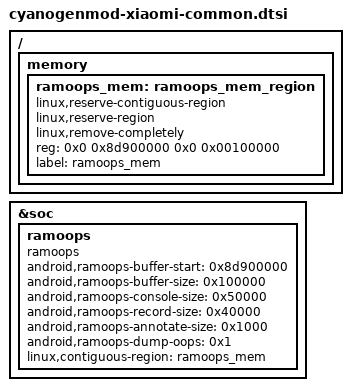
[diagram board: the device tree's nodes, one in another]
/* Copyright (c) 2015, The Linux Foundation. All rights reserved.
 *
 * This program is free software; you can redistribute it and/or modify
 * it under the terms of the GNU General Public License version 2 and
 * only version 2 as published by the Free Software Foundation.
 *
 * This program is distributed in the hope that it will be useful,
 * but WITHOUT ANY WARRANTY; without even the implied warranty of
 * MERCHANTABILITY or FITNESS FOR A PARTICULAR PURPOSE.  See the
 * GNU General Public License for more details.
 */

/ {
	memory {
		ramoops_mem: ramoops_mem_region {
			linux,reserve-contiguous-region;
			linux,reserve-region;
			linux,remove-completely;
			reg = <0x0 0x8d900000 0x0 0x00100000>;
			label = "ramoops_mem";
		};
	};
};

&soc {
	ramoops {
		compatible = "ramoops";
		status = "ok";

		android,ramoops-buffer-start = <0x8d900000>;
		android,ramoops-buffer-size = <0x100000>;
		android,ramoops-console-size = <0x50000>;
		android,ramoops-record-size = <0x40000>;
		android,ramoops-annotate-size = <0x1000>;
		android,ramoops-dump-oops = <0x1>;

		linux,contiguous-region = <&ramoops_mem>;
	};
};
